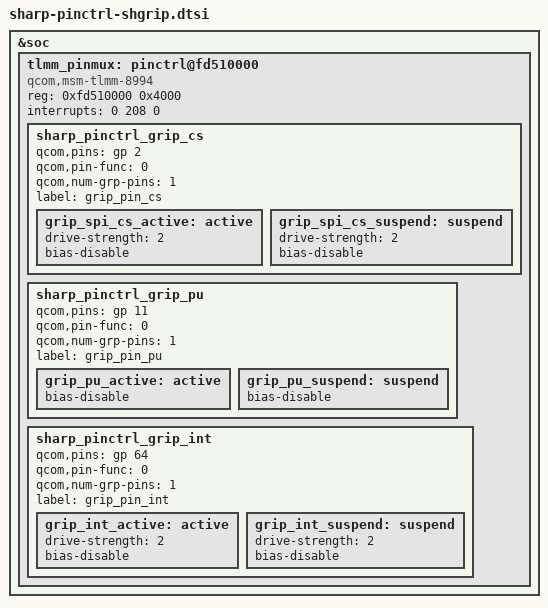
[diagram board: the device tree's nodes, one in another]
/* Copyright (c) 2013-2014, The Linux Foundation. All rights reserved.
 *
 * This program is free software; you can redistribute it and/or modify
 * it under the terms of the GNU General Public License version 2 and
 * only version 2 as published by the Free Software Foundation.
 *
 * This program is distributed in the hope that it will be useful,
 * but WITHOUT ANY WARRANTY; without even the implied warranty of
 * MERCHANTABILITY or FITNESS FOR A PARTICULAR PURPOSE.  See the
 * GNU General Public License for more details.
 */

&soc {
	tlmm_pinmux: pinctrl@fd510000 {
		compatible = "qcom,msm-tlmm-8994", "qcom,msm-tlmm-8974";
		reg = <0xfd510000 0x4000>;
		interrupts = <0 208 0>;

		/*****************************************/
		/*  pinctrl customize setting            */
		/*  GripSensor                           */
		/*****************************************/

		sharp_pinctrl_grip_cs{
			qcom,pins = <&gp 2>;
			qcom,pin-func = <0>;
			qcom,num-grp-pins = <1>;
			label = "grip_pin_cs";
			grip_spi_cs_active: active {
				drive-strength = <2>;
				bias-disable;
			};
			grip_spi_cs_suspend: suspend {
				drive-strength = <2>;
				bias-disable;
			};
		};
		sharp_pinctrl_grip_pu{
			qcom,pins = <&gp 11>;
			qcom,pin-func = <0>;
			qcom,num-grp-pins = <1>;
			label = "grip_pin_pu";
			grip_pu_active: active {
				bias-disable;
			};
			grip_pu_suspend: suspend {
				bias-disable;
			};
		};
		sharp_pinctrl_grip_int{
			qcom,pins = <&gp 64>;
			qcom,pin-func = <0>;
			qcom,num-grp-pins = <1>;
			label = "grip_pin_int";
			grip_int_active: active {
				drive-strength = <2>;
				bias-disable;
			};
			grip_int_suspend: suspend {
				drive-strength = <2>;
				bias-disable;
			};
		};
	};
};
